AUTOSAR XML (schema 00046)
package /Component_Composition_2_package
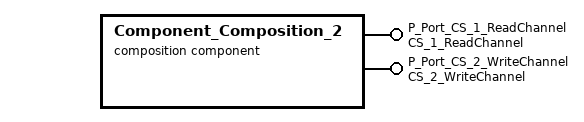
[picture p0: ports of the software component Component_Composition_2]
  composition sw component type Component_Composition_2
    provide port P_Port_CS_1_ReadChannel: provided-interface=CS_1_ReadChannel
    provide port P_Port_CS_2_WriteChannel: provided-interface=CS_2_WriteChannel
    component Component_Composition_2_Prototype_1: type=IOA_SWC_1
